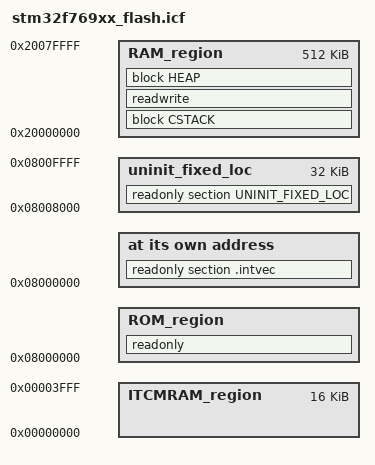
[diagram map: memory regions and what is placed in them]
/*###ICF### Section handled by ICF editor, don't touch! ****/
/*-Editor annotation file-*/
/* IcfEditorFile="$TOOLKIT_DIR$\config\ide\IcfEditor\cortex_v1_0.xml" */
/*-Specials-*/
define symbol __ICFEDIT_intvec_start__ = 0x08000000;
export symbol __ICFEDIT_intvec_start__;

/*-Memory Regions-*/
define symbol __ICFEDIT_region_ROM_start__     = 0x08000000;
define symbol __ICFEDIT_region_ROM_end__       = 0x081FFFFF;
define symbol __ICFEDIT_region_RAM_start__     = 0x20000000;
define symbol __ICFEDIT_region_RAM_end__       = 0x2007FFFF;
define symbol __ICFEDIT_region_ITCMRAM_start__ = 0x00000000;
define symbol __ICFEDIT_region_ITCMRAM_end__   = 0x00003FFF;
/*-Sizes-*/
define symbol __ICFEDIT_size_cstack__ = 0x1000;
/* heap +32k due to the size of the smallest sector */
define symbol __ICFEDIT_size_heap__   = 0x17800;
/**** End of ICF editor section. ###ICF###*/

define memory mem with size = 4G;

/* Definition of the static memory section for the user configuration: TLS certificates, key, and wifi configuration data.
 * A whole sector must be reserved so that the linker does not place initialized data there, which 
 * would cause a sector erase when the firmware image is programmed.
 * This mapping is valid whatever the bank organization:
 *    Seen as 1 x 32k sector at 0x08008000 in single bank case
 *    Seen as 2 x 16k sectors at 0x08008000 in dual bank case.
 */
define symbol __ICFEDIT_region_FIXED_LOC_start__ = 0x08008000;
export symbol __ICFEDIT_region_FIXED_LOC_start__;
define region uninit_fixed_loc = mem:[from __ICFEDIT_region_FIXED_LOC_start__ size 32K];

define region ROM_region      = mem:[from __ICFEDIT_region_ROM_start__   to __ICFEDIT_region_ROM_end__] - uninit_fixed_loc;
define region RAM_region      = mem:[from __ICFEDIT_region_RAM_start__   to __ICFEDIT_region_RAM_end__];
define region ITCMRAM_region  = mem:[from __ICFEDIT_region_ITCMRAM_start__ to __ICFEDIT_region_ITCMRAM_end__];


define block CSTACK    with alignment = 8, size = __ICFEDIT_size_cstack__   { };
define block HEAP      with alignment = 8, size = __ICFEDIT_size_heap__     { };

initialize by copy { readwrite };
do not initialize  { section .noinit };

place at address mem:__ICFEDIT_intvec_start__ { readonly section .intvec };

place in ROM_region   { readonly };
place in RAM_region   { block CSTACK,
                        readwrite,
                        block HEAP };
						
place in uninit_fixed_loc  { readonly section UNINIT_FIXED_LOC };
